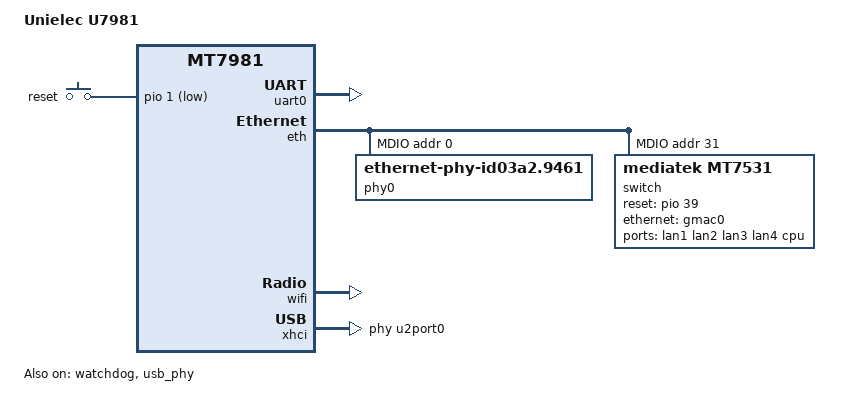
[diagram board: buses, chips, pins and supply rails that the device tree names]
// SPDX-License-Identifier: GPL-2.0-or-later OR MIT

/dts-v1/;
#include "mt7981.dtsi"
/ {
	model = "Unielec U7981";
	compatible = "unielec,u7981", "mediatek,mt7981";

	// aliases {
	// 	serial0 = &uart0;
	// 	led-boot = &led_white;
	// 	led-failsafe = &led_white;
	// 	led-running = &led_blue;
	// 	led-upgrade = &led_blue;
	// 	label-mac-device = &gmac1;
	// };

	chosen {
		bootargs = "console=ttyS0,115200n1 loglevel=8  \
				earlycon=uart8250,mmio32,0x11002000 \
				";
		// bootargs-override = "console=ttyS0,115200n8 rootwait root=/dev/mmcblk0p7";root=/dev/mmcblk0p6 rootfstype=squashfs,f2fs
		// stdout-path = "serial0:115200n8";
	};

	// memory {
	// 	// fpga ddr2: 128MB*2
	// 	reg = <0 0x40000000 0 0x10000000>;
	// };

	gpio-keys {
		compatible = "gpio-keys";
		reset {
			label = "reset";
			linux,code = <KEY_RESTART>;
			gpios = <&pio 1 GPIO_ACTIVE_LOW>;
		};
	};

	// leds {
	// 	compatible = "gpio-leds";

	// 	led_blue: dome-blue {
	// 		label = "blue:dome";
	// 		gpios = <&pio 9 GPIO_ACTIVE_HIGH>;
	// 	};

	// 	led_white: dome-white {
	// 		label = "white:dome";
	// 		gpios = <&pio 34 GPIO_ACTIVE_HIGH>;
	// 	};
	// };

	// reg_3p3v: regulator-3p3v {
	// 	compatible = "regulator-fixed";
	// 	regulator-name = "fixed-3.3V";
	// 	regulator-min-microvolt = <3300000>;
	// 	regulator-max-microvolt = <3300000>;
	// 	regulator-boot-on;
	// 	regulator-always-on;
	// };
};

&uart0 {
	status = "okay";
};

&watchdog {
	status = "okay";
};

// &mmc0 {
// 	pinctrl-names = "default", "state_uhs";
// 	pinctrl-0 = <&mmc0_pins_default>;
// 	pinctrl-1 = <&mmc0_pins_uhs>;
// 	bus-width = <8>;
// 	max-frequency = <52000000>;
// 	cap-mmc-highspeed;
// 	vmmc-supply = <&reg_3p3v>;
// 	non-removable;
// 	status = "okay";
// };

&eth {
	pinctrl-names = "default";
	pinctrl-0 = <&mdio_pins &gbe_led0_pins &gbe_led1_pins>;
	status = "okay";

	gmac0: mac@0 {
		compatible = "mediatek,eth-mac";
		reg = <0>;
		phy-mode = "2500base-x";

		fixed-link {
			speed = <2500>;
			full-duplex;
			pause;
		};
	};

	gmac1: mac@1 {
		compatible = "mediatek,eth-mac";
		reg = <1>;
		phy-mode = "gmii";
		phy-handle = <&phy0>;
		// phy-handle = <&int_gbe_phy>;
		// nvmem-cell-names = "mac-address";
		// nvmem-cells = <&macaddr_eeprom_0>;
	};

	mdio: mdio-bus {
		#address-cells = <1>;
		#size-cells = <0>;

		phy0: ethernet-phy@0 {
			compatible = "ethernet-phy-id03a2.9461";
			reg = <0>;
			phy-mode = "gmii";
			nvmem-cells = <&phy_calibration>;
			nvmem-cell-names = "phy-cal-data";
		};

		switch@0 {
			compatible = "mediatek,mt7531";
			reg = <31>;
			reset-gpios = <&pio 39 0>;

			ports {
				#address-cells = <1>;
				#size-cells = <0>;

				port@0 {
					reg = <0>;
					label = "lan1";
				};

				port@1 {
					reg = <1>;
					label = "lan2";
				};

				port@2 {
					reg = <2>;
					label = "lan3";
				};

				port@3 {
					reg = <3>;
					label = "lan4";
				};

				port@6 {
					reg = <6>;
					label = "cpu";
					ethernet = <&gmac0>;
					phy-mode = "2500base-x";

					fixed-link {
						speed = <2500>;
						full-duplex;
						pause;
					};
				};
			};
		};
	};
};

// &hnat {
// 	mtketh-wan = "eth1";
// 	mtketh-lan = "lan";
// 	mtketh-max-gmac = <2>;
// 	status = "okay";
// };

// &spi1 {
// 	pinctrl-names = "default";
// 	pinctrl-0 = <&spic_pins>;
// 	status = "disabled";
// };

// &pio {

// 	spic_pins: spi1-pins {
// 		mux {
// 			function = "spi";
// 			groups = "spi1_1";
// 		};
// 	};

// 	mmc0_pins_default: mmc0-pins-default {
// 		mux {
// 			function = "flash";
// 			groups = "emmc_45";
// 		};
// 	};

// 	mmc0_pins_uhs: mmc0-pins-uhs {
// 		mux {
// 			function = "flash";
// 			groups = "emmc_45";
// 		};
// 	};
// };

&wifi {
	status = "okay";
	// nvmem-cell-names = "eeprom";
	// nvmem-cells = <&eeprom_factory_0>;
};

&usb_phy {
	status = "okay";
};

&xhci {
	// mediatek,u3p-dis-msk = <0x1>;
	mediatek,u3p-dis-msk = <0x0>;
	phys = <&u2port0 PHY_TYPE_USB2>,
	       <&u3port0 PHY_TYPE_USB3>;
	status = "okay";
};
